AUTOSAR XML (schema 00044)
standard types defined: boolean, float32, float64, sint16, sint32, sint64, sint8, uint16, uint32, uint64, uint8
package /AUTOSAR_Platform/CompuMethods
  compu method CompuMethod_boolean: 0=FALSE, 1=TRUE
package /AUTOSAR_Platform/DataConstrs
  range DataConstr_boolean: raw 0..1
  range DataConstr_float32: raw -3.4028235e+38..3.4028235e+38
  range DataConstr_float64: raw -1.7976931348623157e+308..1.7976931348623157e+308
  range DataConstr_sint16: raw -32768..32767
  range DataConstr_sint32: raw -2147483648..2147483647
  range DataConstr_sint64: raw -9223372036854775808..9223372036854775807
  range DataConstr_sint8: raw -128..127
  range DataConstr_uint16: raw 0..65535
  range DataConstr_uint32: raw 0..4294967295
  range DataConstr_uint64: raw 0..18446744073709551615
  range DataConstr_uint8: raw 0..255
package /VW/Global/PhysicalDimensions
  physical dimension PD_undefined_unit_helper_nounit
package /VW/Global/Units
  unit Unit_nounit: display-name=nounit, factor-si-to-unit=1.0, offset-si-to-unit=0, physical-dimension=PD_undefined_unit_helper_nounit
package /com/applied/arche/lights/ApplicationDataTypes
  app type ADT_boolean: category=BOOLEAN, compu {0=FALSE, 1=TRUE}
package /com/applied/arche/lights/ConstantSpecifications
  4 x constant specification:
    C_INIT_ADT_HazardActivate_hazard_activation: value-spec=ADT_Hazard_Activation_ON
    C_INIT_ADT_StalkControl_hazard_triggered: value-spec=ADT_Hazard_Stalk_ON
    C_INIT_IF_ALU_L_440_PWM_DE_ALU_L_440_PWM: value-spec=0
    C_INIT_IF_ALU_R_440_PWM_DE_ALU_R_440_PWM: value-spec=0
package /com/applied/arche/lights/DataTypeMappingSets
  data type mapping set DTMS_FrontHazardsMaster
  data type mapping set DTMS_FrontLightControlMaster
package /com/applied/arche/lights/PortInterfaces
  4 x sender receiver interface:
    ADT_HazardActivate
      data hazard_activation
    ADT_StalkControl
      data hazard_triggered
    IF_ALU_L_440_PWM
      data DE_ALU_L_440_PWM
    IF_ALU_R_440_PWM
      data DE_ALU_R_440_PWM
package /com/applied/arche/lights/SwComponentTypes
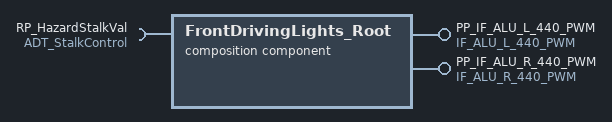
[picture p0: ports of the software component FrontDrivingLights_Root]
  composition sw component type FrontDrivingLights_Root
    provide port PP_IF_ALU_L_440_PWM: nonqueued-sender-com-spec{data-element=DE_ALU_L_440_PWM, init-value=constant-reference=C_INIT_IF_ALU_L_440_PWM_DE_ALU_L_440_PWM}, provided-interface=IF_ALU_L_440_PWM
    provide port PP_IF_ALU_R_440_PWM: nonqueued-sender-com-spec{data-element=DE_ALU_R_440_PWM, init-value=constant-reference=C_INIT_IF_ALU_R_440_PWM_DE_ALU_R_440_PWM}, provided-interface=IF_ALU_R_440_PWM
    require port RP_HazardStalkVal: nonqueued-receiver-com-spec{data-element=hazard_triggered, init-value=constant-reference=C_INIT_ADT_StalkControl_hazard_triggered}, required-interface=ADT_StalkControl
    component I_FrontHazardsMaster: type=FrontHazardsMaster
    component I_FrontLightControlMaster: type=FrontLightControlMaster
    delegate I_FrontHazardsMaster.RP_ADT_StalkControl <-> outer port RP_HazardStalkVal
    connect I_FrontHazardsMaster.PP_ADT_HazardActivate -> I_FrontLightControlMaster.RP_ADT_HazardActivate
    delegate I_FrontLightControlMaster.PP_IF_ALU_L_440_PWM <-> outer port FrontDrivingLights_Root/PP_IF_ALU_L_440_PWM
    delegate I_FrontLightControlMaster.PP_IF_ALU_R_440_PWM <-> outer port FrontDrivingLights_Root/PP_IF_ALU_R_440_PWM
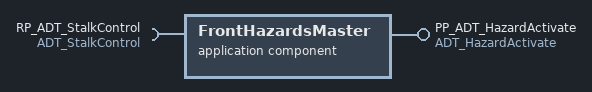
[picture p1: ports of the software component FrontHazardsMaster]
  application sw component type FrontHazardsMaster
    provide port PP_ADT_HazardActivate: nonqueued-sender-com-spec{data-element=hazard_activation, init-value=constant-reference=C_INIT_ADT_HazardActivate_hazard_activation}, provided-interface=ADT_HazardActivate
    require port RP_ADT_StalkControl: nonqueued-receiver-com-spec{data-element=hazard_triggered, init-value=constant-reference=C_INIT_ADT_StalkControl_hazard_triggered}, required-interface=ADT_StalkControl
    symbol props FrontHazardsMaster_symbol: symbol=FrontHazardsMaster
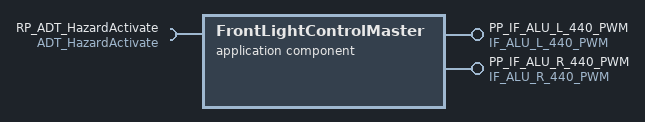
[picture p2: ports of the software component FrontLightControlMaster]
  application sw component type FrontLightControlMaster
    provide port PP_IF_ALU_L_440_PWM: nonqueued-sender-com-spec{data-element=DE_ALU_L_440_PWM, init-value=constant-reference=C_INIT_IF_ALU_L_440_PWM_DE_ALU_L_440_PWM}, provided-interface=IF_ALU_L_440_PWM
    provide port PP_IF_ALU_R_440_PWM: nonqueued-sender-com-spec{data-element=DE_ALU_R_440_PWM, init-value=constant-reference=C_INIT_IF_ALU_R_440_PWM_DE_ALU_R_440_PWM}, provided-interface=IF_ALU_R_440_PWM
    require port RP_ADT_HazardActivate: nonqueued-receiver-com-spec{data-element=hazard_activation, init-value=constant-reference=C_INIT_ADT_HazardActivate_hazard_activation}, required-interface=ADT_HazardActivate
    symbol props FrontLightControlMaster_symbol: symbol=FrontLightControlMaster
